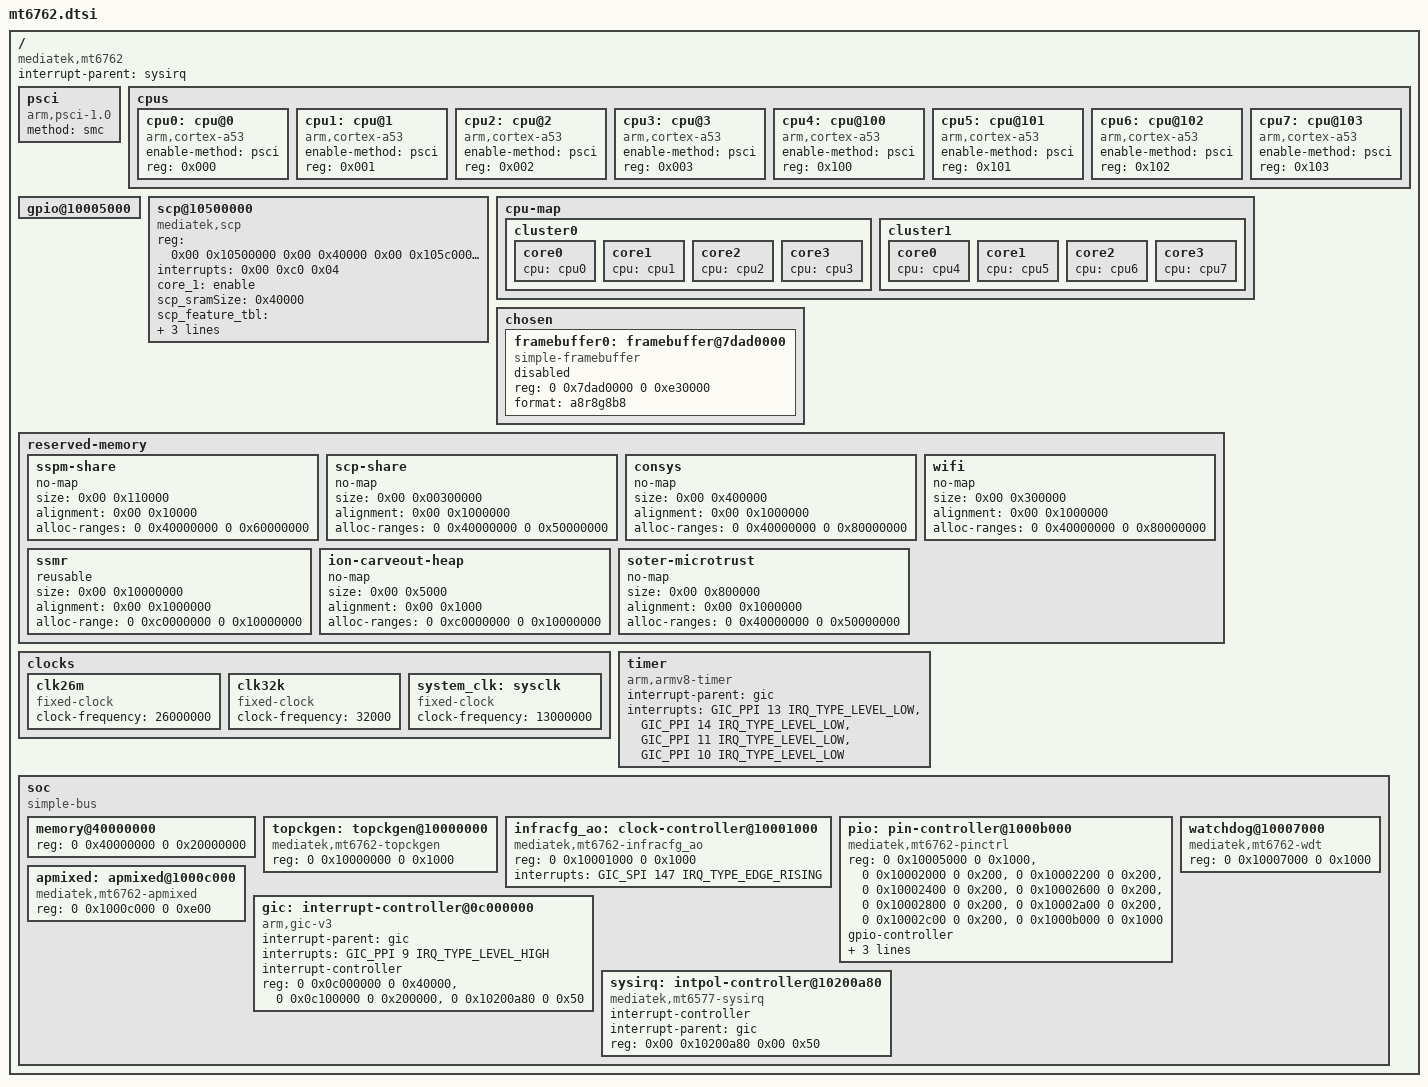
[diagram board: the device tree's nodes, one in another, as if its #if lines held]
// SPDX-License-Identifier: (GPL-2.0 OR MIT)
/*
 * Copyright (c) 2023 Brandon Boese
 */

#include <dt-bindings/interrupt-controller/irq.h>
#include <dt-bindings/interrupt-controller/arm-gic.h>
#include <dt-bindings/clock/mediatek,mt6762-clk.h>
#include <dt-bindings/gce/mt6762-gce.h>
#include <dt-bindings/phy/phy.h>

/ {
    compatible = "mediatek,mt6762";
    interrupt-parent = <&sysirq>;
    #address-cells = <2>;
    #size-cells = <2>;

    psci {
        compatible      = "arm,psci-1.0";
        method          = "smc";
    };

    cpus {
        #address-cells = <1>;
        #size-cells = <0>;

        cpu0: cpu@0 {
            device_type = "cpu";
            compatible = "arm,cortex-a53";
            enable-method = "psci";
            reg = <0x000>;
        };

        cpu1: cpu@1 {
            device_type = "cpu";
            compatible = "arm,cortex-a53";
            enable-method = "psci";
            reg = <0x001>;
        };

        cpu2: cpu@2 {
            device_type = "cpu";
            compatible = "arm,cortex-a53";
            enable-method = "psci";
            reg = <0x002>;
        };

        cpu3: cpu@3 {
            device_type = "cpu";
            compatible = "arm,cortex-a53";
            enable-method = "psci";
            reg = <0x003>;
        };

        cpu4: cpu@100 {
            device_type = "cpu";
            compatible = "arm,cortex-a53";
            enable-method = "psci";
            reg = <0x100>;
        };

        cpu5: cpu@101 {
            device_type = "cpu";
            compatible = "arm,cortex-a53";
            enable-method = "psci";
            reg = <0x101>;
        };

        cpu6: cpu@102 {
            device_type = "cpu";
            compatible = "arm,cortex-a53";
            enable-method = "psci";
            reg = <0x102>;
        };

        cpu7: cpu@103 {
            device_type = "cpu";
            compatible = "arm,cortex-a53";
            enable-method = "psci";
            reg = <0x103>;
        };
    };

    /* The following are required by stock bootloader to merge with minimal DTBO */
	gpio@10005000 {
		linux,phandle = <0xdead>;
		phandle = <0xdead>;
	};
	__symbols__ {
		gpio = "/gpio@10005000";
	};

	scp@10500000 {
		compatible = "mediatek,scp";
		status = "okay";
		reg = <0x00 0x10500000 0x00 0x40000 0x00 0x105c0000 0x00 0x3000 0x00 0x105c4000 0x00 0x1000 0x00 0x105d4000 0x00 0x6000>;
		interrupts = <0x00 0xc0 0x04>;
		core_1 = "enable";
		scp_sramSize = <0x40000>;
		scp_feature_tbl = <0x00 0x2f 0x01 0x164 0x02 0x3e 0x03 0x2f 0x04 0x1a 0x05 0x00 0x06 0xc8 0x07 0x00 0x08 0x64 0x09 0x0a>;
		scp_mem_key = "mediatek,reserve-memory-scp_share";
		scp_mem_tbl = <0x01 0x100000 0x04 0x200000>;
	};

    cpu-map {
        cluster0 {
            core0 {
                cpu = <&cpu0>;
            };
            core1 {
                cpu = <&cpu1>;
            };
            core2 {
                cpu = <&cpu2>;
            };
            core3 {
                cpu = <&cpu3>;
            };
        };

        cluster1 {
            core0 {
                cpu = <&cpu4>;
            };
            core1 {
                cpu = <&cpu5>;
            };
            core2 {
                cpu = <&cpu6>;
            };
            core3 {
                cpu = <&cpu7>;
            };
        };
    };

    chosen {
        #address-cells = <2>;
        #size-cells = <2>;
        ranges;

        /*
         * Use display framebuffer setup by the lk bootloader for simplefb
         * FIXME: text is rendered fine, but any images not?!
         */
        framebuffer0: framebuffer@7dad0000 {
            compatible = "simple-framebuffer";
            reg = <0 0x7dad0000 0 0xe30000>;
            format = "a8r8g8b8";
            status = "disabled";
        };
    };

    reserved-memory {
        #address-cells = <2>;
        #size-cells = <2>;
        ranges;

        sspm-share {
            no-map;
            status = "okay";
#ifdef CONFIG_MTK_GMO_RAM_OPTIMIZE
            size = <0x00 0x110000>;
#else
            size = <0x00 0x510000>;
#endif
            alignment = <0x00 0x10000>;
            alloc-ranges = <0 0x40000000 0 0x60000000>;
        };

        scp-share {
            no-map;
            size = <0x00 0x00300000>;
            alignment = <0x00 0x1000000>;
            alloc-ranges = <0 0x40000000 0 0x50000000>;
        };

        consys {
            no-map;
            size = <0x00 0x400000>;
            alignment = <0x00 0x1000000>;
            alloc-ranges = <0 0x40000000 0 0x80000000>;
        };

        wifi {
            no-map;
            size = <0x00 0x300000>;
            alignment = <0x00 0x1000000>;
            alloc-ranges = <0 0x40000000 0 0x80000000>;
        };

        /* FIXME: I have no idea what this does. */
        ssmr {
            /* FIXME: Was originally reusable in the downstream dts
             * but was still in the reserved memory section?
             */
            reusable;
            size = <0x00 0x10000000>;
            alignment = <0x00 0x1000000>;
            alloc-range = <0 0xc0000000 0 0x10000000>;
        };

        /* FIXME: I have no idea what this does. Something to do with a C heap? */
        ion-carveout-heap {
            no-map;
            size = <0x00 0x5000>;
            alignment = <0x00 0x1000>;
            alloc-ranges = <0 0xc0000000 0 0x10000000>;
        };

        /* FIXME: is this even required on mainline?? */

#ifdef CONFIG_MICROTRUST_TEE_SUPPORT
        soter-microtrust {
            no-map;
#if defined(CONFIG_MTK_SEC_VIDEO_PATH_SUPPORT) || \
    defined(CONFIG_MTK_CAM_SECURITY_SUPPORT)
            size = <0x00 0x800000>;
            alignment = <0x00 0x1000000>;
#else
            size = <0x00 0x200000>;
            alignment = <0x00 0x200000>;
#endif
            alloc-ranges = <0 0x40000000 0 0x50000000>;
        };
#endif
    };

    clocks {
		clk26m: clk26m {
			compatible = "fixed-clock";
			#clock-cells = <0>;
			clock-frequency = <26000000>;
		};

		clk32k: clk32k {
			compatible = "fixed-clock";
			#clock-cells = <0>;
			clock-frequency = <32000>;
		};

		system_clk: sysclk {
			compatible = "fixed-clock";
			#clock-cells = <0>;
			clock-frequency = <13000000>;
		};
	};

    timer {
        compatible = "arm,armv8-timer";
        interrupt-parent = <&gic>;
        interrupts = <GIC_PPI 13 IRQ_TYPE_LEVEL_LOW>,
                     <GIC_PPI 14 IRQ_TYPE_LEVEL_LOW>,
                     <GIC_PPI 11 IRQ_TYPE_LEVEL_LOW>,
                     <GIC_PPI 10 IRQ_TYPE_LEVEL_LOW>;
    };

    soc {
        /* FIXME: Copied from mt6763. Confirm works with mt6762 */
        #address-cells = <2>;
        #size-cells = <2>;
        compatible = "simple-bus";
        ranges;
        /* End FIXME */

        memory@40000000 {
            device_type = "memory";
            reg = <0 0x40000000 0 0x20000000>;
        };

        topckgen: topckgen@10000000 {
            compatible = "mediatek,mt6762-topckgen";
            reg = <0 0x10000000 0 0x1000>;
            #clock-cells = <1>;
        };

        infracfg_ao: clock-controller@10001000 {
            compatible = "mediatek,mt6762-infracfg_ao";
            reg = <0 0x10001000 0 0x1000>;
            interrupts = <GIC_SPI 147 IRQ_TYPE_EDGE_RISING>;
            #clock-cells = <1>;
        };

        pio: pin-controller@1000b000 {
            compatible = "mediatek,mt6762-pinctrl";
            reg = <0 0x10005000 0 0x1000>,
                  <0 0x10002000 0 0x200>,
                  <0 0x10002200 0 0x200>,
                  <0 0x10002400 0 0x200>,
                  <0 0x10002600 0 0x200>,
                  <0 0x10002800 0 0x200>,
                  <0 0x10002a00 0 0x200>,
                  <0 0x10002c00 0 0x200>,
                  <0 0x1000b000 0 0x1000>;
            reg-names = "gpio",
                        "io_cfg_lt",
                        "io_cfg_lm",
                        "io_cfg_lb",
                        "io_cfg_bl",
                        "io_cfg_rr",
                        "io_cfg_rb",
                        "io_cfg_rt",
                        "eint";
            gpio-controller;
            #gpio-cells = <2>;
            gpio-ranges = <&pio 0 0 179>;
            interrupt-controller;
            interrupts = <GIC_SPI 171 IRQ_TYPE_LEVEL_HIGH>;
            #interrupt-cells = <2>;
        };

        watchdog@10007000 {
            compatible = "mediatek,mt6762-wdt",
                         "mediatek,mt6589-wdt";
            reg = <0 0x10007000 0 0x1000>;
        };

        apmixed: apmixed@1000c000 {
            compatible = "mediatek,mt6762-apmixed";
            reg = <0 0x1000c000 0 0xe00>;
            #clock-cells = <1>;
        };

        /*
        usb2: usb@11200000 {
			compatible = "mediatek,mt6762-musb", "mediatek,mtk-musb";
			reg = <0 0x11200000 0 0x10000>,
		          <0 0x11CC0000 0 0x10000>;
			interrupts = <GIC_SPI 73 IRQ_TYPE_LEVEL_LOW>;
			interrupt-names = "mc";
			clocks = <&infracfg_ao CLK_IFR_ICUSB>,
                     <&system_clk CLK_TOP_USB_TOP_SEL>,
                     <&topckgen CLK_TOP_UNIVPLL3_D4>;
			clock-names = "main", "mcu", "univpll";
			phys = <&usb2port0 PHY_TYPE_USB2>;
			dr_mode = "otg";
			status = "disabled";
	    };

        usb2phy: phy@11210000 {
			compatible = "mediatek,mt6762-tphy", "mediatek,generic-tphy-v1";
			reg = <0 0x11210000 0 0x10000>;
			#address-cells = <2>;
			#size-cells = <2>;
			ranges;

			status = "disabled";

			usb2port0: usb-phy@11230000 {
				reg = <0 0x11230000 0 0x10000>;
				clocks = <&infracfg_ao CLK_IFR_ICUSB>;
				clock-names = "ref";
				#phy-cells = <1>;
			};

			usb2port1: usb-phy@11240000 {
				reg = <0 0x11240000 0 0x10000>;
				clocks = <&infracfg_ao CLK_IFR_ICUSB>;
				clock-names = "ref";
				#phy-cells = <1>;
			};

			usb2port2: usb-phy@11250000 {
				reg = <0 0x11250000 0 0x10000>;
				clocks = <&infracfg_ao CLK_IFR_ICUSB>;
				clock-names = "ref";
				#phy-cells = <1>;
			};

			usb2port3: usb-phy@11260000 {
				reg = <0 0x11250000 0 0x10000>;
				clocks = <&infracfg_ao CLK_IFR_ICUSB>;
				clock-names = "ref";
				#phy-cells = <1>;
			};
		};
        */

        gic: interrupt-controller@0c000000 {
            compatible = "arm,gic-v3";
            #interrupt-cells = <3>;
            interrupt-parent = <&gic>;
            interrupts = <GIC_PPI 9 IRQ_TYPE_LEVEL_HIGH>;
            interrupt-controller;
            reg = <0 0x0c000000 0 0x40000>, // distributor
                  <0 0x0c100000 0 0x200000>, // redistributor
                  <0 0x10200a80 0 0x50>; // intpol
        };

        sysirq: intpol-controller@10200a80 {
            compatible = "mediatek,mt6577-sysirq",
                         "mediatek,mt6762-sysirq";
            interrupt-controller;
            #interrupt-cells = <3>;
            interrupt-parent = <&gic>;
            reg = <0x00 0x10200a80 0x00 0x50>;
        };
    };
};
